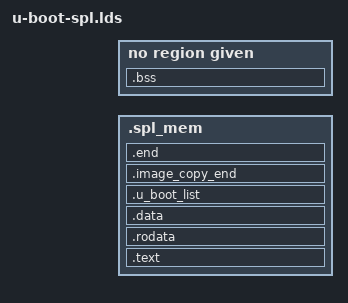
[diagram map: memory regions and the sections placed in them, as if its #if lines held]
/* SPDX-License-Identifier: GPL-2.0+ */
/*
 * (C) Copyright 2021
 * Huanghuafeng@semidrive.com
 */

MEMORY { .spl_mem : ORIGIN = IMAGE_TEXT_BASE, LENGTH = IMAGE_MAX_SIZE }
MEMORY { .bss_mem : ORIGIN = CONFIG_SPL_BSS_START_ADDR, \
		LENGTH = CONFIG_SPL_BSS_MAX_SIZE }
OUTPUT_FORMAT("elf64-littleaarch64", "elf64-littleaarch64", "elf64-littleaarch64")
OUTPUT_ARCH(aarch64)
ENTRY(_start)
SECTIONS
{
	. = 0x00000000;

	. = ALIGN(8);
	.text : {
		*(.__image_copy_start)
		CPUDIR/start.o (.text*)
		*(.text*)
	} > .spl_mem

	. = ALIGN(8);
	.rodata : {
		*(SORT_BY_ALIGNMENT(SORT_BY_NAME(.rodata*)))
	} > .spl_mem

	. = ALIGN(8);
	.data : {
		*(.data*)
	} > .spl_mem

	. = ALIGN(8);
	.u_boot_list : {
		KEEP(*(SORT(.u_boot_list*)));
	} > .spl_mem

	. = ALIGN(8);
	.image_copy_end : {
		*(.__image_copy_end)
	} > .spl_mem

	. = ALIGN(8);
	.end : {
		*(.__end)
	} > .spl_mem

	_image_binary_end = .;

	.bss : {
		__bss_start = .;
		*(.*bss*)
		__bss_end = .;
	} > .bss_mem

	/DISCARD/ : { *(.dynsym) }
	/DISCARD/ : { *(.dynstr*) }
	/DISCARD/ : { *(.dynamic*) }
	/DISCARD/ : { *(.plt*) }
	/DISCARD/ : { *(.interp*) }
	/DISCARD/ : { *(.gnu*) }
}

#if defined(IMAGE_MAX_SIZE)
ASSERT(__image_copy_end - __image_copy_start <= (IMAGE_MAX_SIZE), \
		"SPL image too big");
#endif

#if defined(CONFIG_SPL_BSS_MAX_SIZE)
ASSERT(__bss_end - __bss_start <= (CONFIG_SPL_BSS_MAX_SIZE), \
	"SPL image BSS too big");
#endif


